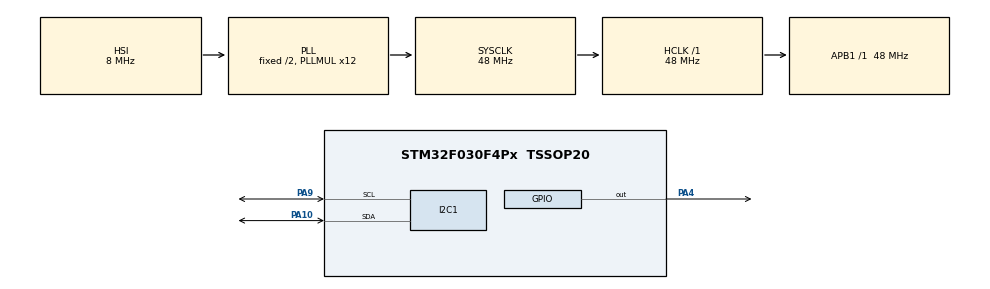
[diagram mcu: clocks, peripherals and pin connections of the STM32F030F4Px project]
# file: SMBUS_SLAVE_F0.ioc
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I2C1.SMBusOwnAddress=0x12
I2C1.Timeout=0x00008249
I2C1.Timing=0x20303E5D
Mcu.Family=STM32F0
Mcu.Name=STM32F030F4Px
Mcu.Package=TSSOP20
NVIC.I2C1_IRQn=true\:0\:0\:false\:false\:true\:true\:true\:true
PA10.Mode=SMBus-two-wire-Interface
PA10.Signal=I2C1_SDA
PA4.Signal=GPIO_Output
PA9.Mode=SMBus-two-wire-Interface
PA9.Signal=I2C1_SCL
PF0-OSC_IN.Mode=HSE-External-Oscillator
PF0-OSC_IN.Signal=RCC_OSC_IN
PF1-OSC_OUT.Mode=HSE-External-Oscillator
PF1-OSC_OUT.Signal=RCC_OSC_OUT
ProjectManager.HeapSize=0x200
ProjectManager.StackSize=0x400
ProjectManager.TargetToolchain=STM32CubeIDE
RCC.AHBFreq_Value=48000000
RCC.APB1Freq_Value=48000000
RCC.APB1TimFreq_Value=48000000
RCC.HCLKFreq_Value=48000000
RCC.I2c1ClockSelection=RCC_I2C1CLKSOURCE_SYSCLK
RCC.PLLMUL=RCC_PLL_MUL12
RCC.SYSCLKFreq_VALUE=48000000
RCC.SYSCLKSource=RCC_SYSCLKSOURCE_PLLCLK
STMicroelectronics.X-CUBE-SMBUS.2.1.0.BSP.number=1
STMicroelectronics.X-CUBE-SMBUS.2.1.0.SMB_pec=0
STMicroelectronics.X-CUBE-SMBUS.2.1.0.SMBusIiPMBusIiStackCcSMbusJjSMBus=true
STMicroelectronics.X-CUBE-SMBUS.2.1.00.BSP.STBoard=false
STMicroelectronics.X-CUBE-SMBUS.2.1.00.BSP.api=Unknown
STMicroelectronics.X-CUBE-SMBUS.2.1.00.BSP.instance=I2C1
STMicroelectronics.X-CUBE-SMBUS.2.1.00.BSP.ip=I2C.*
STMicroelectronics.X-CUBE-SMBUS.2.1.00.BSP.mode=SMBus.*
STMicroelectronics.X-CUBE-SMBUS.2.1.00.BSP.name=SMBus
STMicroelectronics.X-CUBE-SMBUS.2.1.00.BSP.solution=I2C1
VP_STMicroelectronics.X-CUBE-SMBUS_VS_SMbusJjSMBusIiPMBusIiStack_2.0.3_2.1.0.Mode=SMbusJjSMBusIiPMBusIiStack
board=custom

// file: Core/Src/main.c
/* USER CODE BEGIN Header */
/**
  ******************************************************************************
  * @file           : main.c
  * @brief          : Main program body
  ******************************************************************************
  * @attention
  *
  * Copyright (c) 2023 STMicroelectronics.
  * All rights reserved.
  *
  * This software is licensed under terms that can be found in the LICENSE file
  * in the root directory of this software component.
  * If no LICENSE file comes with this software, it is provided AS-IS.
  *
  ******************************************************************************
  */
/* USER CODE END Header */
#include "main.h"

/* USER CODE BEGIN Includes */
#include "stm32_SMBUS_stack.h"
/* USER CODE END Includes */

SMBUS_HandleTypeDef hsmbus1;

/* USER CODE BEGIN PV */
uint8_t toggle_led = 0;
/* USER CODE END PV */

void SystemClock_Config(void);
static void MX_GPIO_Init(void);

int main(void)
{

  /* MCU Configuration--------------------------------------------------------*/

  /* Reset of all peripherals, Initializes the Flash interface and the Systick. */
  HAL_Init();

  /* Configure the system clock */
  SystemClock_Config();

  /* Initialize all configured peripherals */
  MX_GPIO_Init();
  MX_I2C1_SMBUS_Init();
  MX_STACK_SMBUS_Init();
  /* USER CODE BEGIN 2 */
  uint8_t i;

  for (i= 0; i < 20; i++) {
    HAL_GPIO_TogglePin(GPIOA, GPIO_PIN_4);
    HAL_Delay(50);

  }
  /* USER CODE END 2 */

  /* Infinite loop */
  while (1)
  {

    /* USER CODE BEGIN 3 */
    HAL_GPIO_WritePin(GPIOA, GPIO_PIN_4, toggle_led);
  }
  /* USER CODE END 3 */
}

void SystemClock_Config(void)
{
  RCC_OscInitTypeDef RCC_OscInitStruct = {0};
  RCC_ClkInitTypeDef RCC_ClkInitStruct = {0};
  RCC_PeriphCLKInitTypeDef PeriphClkInit = {0};

  /** Initializes the RCC Oscillators according to the specified parameters
  * in the RCC_OscInitTypeDef structure.
  */
  RCC_OscInitStruct.OscillatorType = RCC_OSCILLATORTYPE_HSI;
  RCC_OscInitStruct.HSIState = RCC_HSI_ON;
  RCC_OscInitStruct.HSICalibrationValue = RCC_HSICALIBRATION_DEFAULT;
  RCC_OscInitStruct.PLL.PLLState = RCC_PLL_ON;
  RCC_OscInitStruct.PLL.PLLSource = RCC_PLLSOURCE_HSI;
  RCC_OscInitStruct.PLL.PLLMUL = RCC_PLL_MUL12;
  RCC_OscInitStruct.PLL.PREDIV = RCC_PREDIV_DIV1;
  if (HAL_RCC_OscConfig(&RCC_OscInitStruct) != HAL_OK)
  {
    Error_Handler();
  }

  /** Initializes the CPU, AHB and APB buses clocks
  */
  RCC_ClkInitStruct.ClockType = RCC_CLOCKTYPE_HCLK|RCC_CLOCKTYPE_SYSCLK
                              |RCC_CLOCKTYPE_PCLK1;
  RCC_ClkInitStruct.SYSCLKSource = RCC_SYSCLKSOURCE_PLLCLK;
  RCC_ClkInitStruct.AHBCLKDivider = RCC_SYSCLK_DIV1;
  RCC_ClkInitStruct.APB1CLKDivider = RCC_HCLK_DIV1;

  if (HAL_RCC_ClockConfig(&RCC_ClkInitStruct, FLASH_LATENCY_1) != HAL_OK)
  {
    Error_Handler();
  }
  PeriphClkInit.PeriphClockSelection = RCC_PERIPHCLK_I2C1;
  PeriphClkInit.I2c1ClockSelection = RCC_I2C1CLKSOURCE_SYSCLK;
  if (HAL_RCCEx_PeriphCLKConfig(&PeriphClkInit) != HAL_OK)
  {
    Error_Handler();
  }
}

void MX_I2C1_SMBUS_Init(void)
{

  hsmbus1.Instance = I2C1;
  hsmbus1.Init.Timing = 0x20303E5D;
  hsmbus1.Init.AnalogFilter = SMBUS_ANALOGFILTER_ENABLE;
  hsmbus1.Init.OwnAddress1 = 36;
  hsmbus1.Init.AddressingMode = SMBUS_ADDRESSINGMODE_7BIT;
  hsmbus1.Init.DualAddressMode = SMBUS_DUALADDRESS_DISABLE;
  hsmbus1.Init.OwnAddress2 = 0;
  hsmbus1.Init.OwnAddress2Masks = SMBUS_OA2_NOMASK;
  hsmbus1.Init.GeneralCallMode = SMBUS_GENERALCALL_DISABLE;
  hsmbus1.Init.NoStretchMode = SMBUS_NOSTRETCH_DISABLE;
  hsmbus1.Init.PacketErrorCheckMode = SMBUS_PEC_DISABLE;
  hsmbus1.Init.PeripheralMode = SMBUS_PERIPHERAL_MODE_SMBUS_SLAVE;
  hsmbus1.Init.SMBusTimeout = 0x00008249;
  if (HAL_SMBUS_Init(&hsmbus1) != HAL_OK)
  {
    Error_Handler();
  }

}

static void MX_GPIO_Init(void)
{
  GPIO_InitTypeDef GPIO_InitStruct = {0};

  /* GPIO Ports Clock Enable */
  __HAL_RCC_GPIOF_CLK_ENABLE();
  __HAL_RCC_GPIOA_CLK_ENABLE();

  /*Configure GPIO pin Output Level */
  HAL_GPIO_WritePin(GPIOA, GPIO_PIN_4, GPIO_PIN_RESET);

  /*Configure GPIO pin : PA4 */
  GPIO_InitStruct.Pin = GPIO_PIN_4;
  GPIO_InitStruct.Mode = GPIO_MODE_OUTPUT_PP;
  GPIO_InitStruct.Pull = GPIO_NOPULL;
  GPIO_InitStruct.Speed = GPIO_SPEED_FREQ_LOW;
  HAL_GPIO_Init(GPIOA, &GPIO_InitStruct);

}

/* USER CODE BEGIN 4 */
HAL_StatusTypeDef STACK_SMBUS_ExecuteCommand( SMBUS_StackHandleTypeDef *pStackContext )
{
  uint8_t       *piobuf = NULL;

  /* accessing the IO buffer */
  piobuf = STACK_SMBUS_GetBuffer( pStackContext );

  if ( piobuf == NULL )
  {
    pStackContext->StateMachine |= SMBUS_SMS_ERROR;
  }
  else if ( pStackContext->CurrentCommand == (st_command_t *)&HOST_NOTIFY_PROTOCOL )
  {
    /* host notify command */
    if ( pStackContext->Buffer[0] == SMBUS_ADDR_DEFAULT )
    {
      /* Usually the Host notify is used for ARP, but may not be limited to it */

  /* ARP */
    }
  }
  else    /* Normal device command execution */
  {
    /* Zone config command example implementation */

 /* PMBUS13 */
    /*
      first step is to see if we have a case of extended command
    */
	  if ((pStackContext->CurrentCommand->cmnd_query & WRITE ) == WRITE ) {

	    toggle_led = 1;
	 }

    if ((pStackContext->CurrentCommand->cmnd_query & READ ) == READ ) {
	    toggle_led = 0;
	 }

	  if ((pStackContext->CurrentCommand->cmnd_query & BLOCK ) == BLOCK ) {
	          *piobuf = (pStackContext->CurrentCommand->cmnd_master_Rx_size) - 1U;
	          /* byte size of reply for block read command */
	          /* One byte for size, rest are [size] of data */
	 }
  }
  return STACK_OK;
}
/* USER CODE END 4 */

void Error_Handler(void)
{
  __disable_irq();
  while (1)
  {
  }
}
